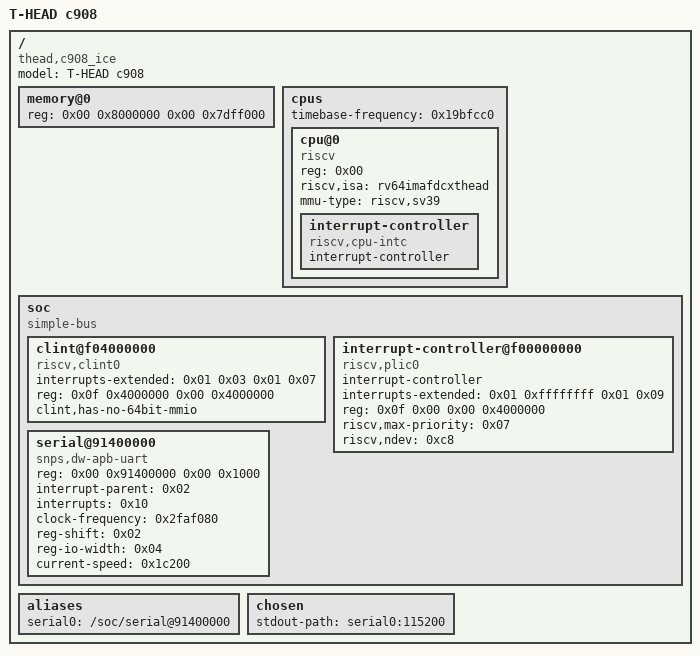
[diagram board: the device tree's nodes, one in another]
/dts-v1/;

/ {
	model = "T-HEAD c908";
	compatible = "thead,c908_ice";
	#address-cells = <0x02>;
	#size-cells = <0x02>;

	memory@0 {
		device_type = "memory";
		reg = <0x00 0x8000000 0x00 0x7dff000>;
	};

	cpus {
		#address-cells = <0x01>;
		#size-cells = <0x00>;
		timebase-frequency = <0x19bfcc0>;

		cpu@0 {
			device_type = "cpu";
			reg = <0x00>;
			status = "okay";
			compatible = "riscv";
			riscv,isa = "rv64imafdcxthead";
			mmu-type = "riscv,sv39";

			interrupt-controller {
				#interrupt-cells = <0x01>;
				#address-cells = <0x01>;
				compatible = "riscv,cpu-intc";
				interrupt-controller;
				phandle = <0x01>;
			};
		};
	};

	soc {
		#address-cells = <0x02>;
		#size-cells = <0x02>;
		compatible = "simple-bus";
		ranges;

		clint@f04000000 {
			compatible = "riscv,clint0";
			interrupts-extended = <0x01 0x03 0x01 0x07>;
			reg = <0x0f 0x4000000 0x00 0x4000000>;
			clint,has-no-64bit-mmio;
		};

		interrupt-controller@f00000000 {
			#interrupt-cells = <0x01>;
			#address-cells = <0x01>;
			compatible = "riscv,plic0";
			interrupt-controller;
			interrupts-extended = <0x01 0xffffffff 0x01 0x09>;
			reg = <0x0f 0x00 0x00 0x4000000>;
			reg-names = "control";
			riscv,max-priority = <0x07>;
			riscv,ndev = <0xc8>;
			phandle = <0x02>;
		};

		serial@91400000 {
			compatible = "snps,dw-apb-uart";
			reg = <0x00 0x91400000 0x00 0x1000>;
			interrupt-parent = <0x02>;
			interrupts = <0x10>;
			clock-frequency = <0x2faf080>;
			/* clocks = <0x03>; */
			clock-names = "baudclk";
			reg-shift = <0x02>;
			reg-io-width = <0x04>;
			current-speed = <0x1c200>;
			status = "okay";
		};

	};


	aliases {
		serial0 = "/soc/serial@91400000";
	};

	chosen {
		stdout-path = "serial0:115200";
	};

};
